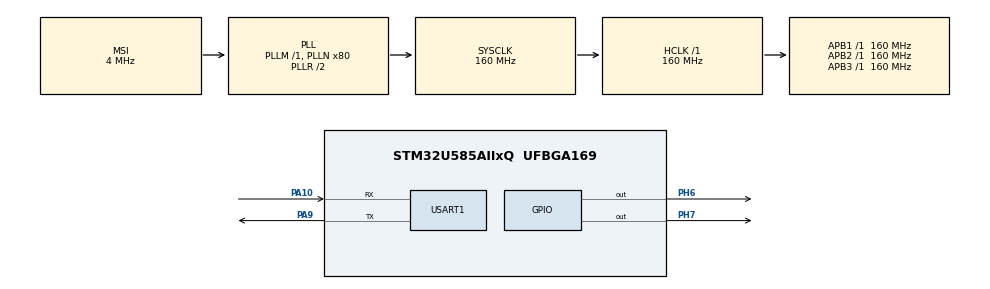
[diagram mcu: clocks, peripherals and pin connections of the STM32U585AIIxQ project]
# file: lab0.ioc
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CORTEX_M33_NS.userName=CORTEX_M33
Mcu.Family=STM32U5
Mcu.Name=STM32U585AIIxQ
Mcu.Package=UFBGA169
NVIC.PriorityGroup=NVIC_PRIORITYGROUP_4
PA10.Mode=Asynchronous
PA10.Signal=USART1_RX
PA9.Mode=Asynchronous
PA9.Signal=USART1_TX
PH6.Signal=GPIO_Output
PH7.Signal=GPIO_Output
PWR.PowerMode=PWR_SMPS_SUPPLY
ProjectManager.HeapSize=0x200
ProjectManager.StackSize=0x400
ProjectManager.TargetToolchain=STM32CubeIDE
RCC.ADCFreq_Value=16000000
RCC.AHBFreq_Value=160000000
RCC.APB1Freq_Value=160000000
RCC.APB1TimFreq_Value=160000000
RCC.APB2Freq_Value=160000000
RCC.APB2TimFreq_Value=160000000
RCC.APB3Freq_Value=160000000
RCC.CortexFreq_Value=160000000
RCC.DACCLockSelectionVirtual=RCC_DAC1CLKSOURCE_LSI
RCC.DACCLockSelectionVirtualString=RCC_DAC1CLKSOURCE_LSI
RCC.EPOD_VALUE=4000000
RCC.HCLKFreq_Value=160000000
RCC.HSE_VALUE=16000000
RCC.HSI48_VALUE=48000000
RCC.HSI_VALUE=16000000
RCC.LSE_VALUE=32768
RCC.LSIDIV_VALUE=32000
RCC.MSI_VALUE=4000000
RCC.PLLN=80
RCC.SYSCLKFreq_VALUE=160000000
RCC.SYSCLKSource=RCC_SYSCLKSOURCE_PLLCLK
RCC.USBFreq_Value=48000000
RCC.VCOOutputFreq_Value=320000000
USART1.VirtualMode-Asynchronous=VM_ASYNC
VP_ICACHE_VS_ICACHE.Mode=DefaultMode
VP_LPBAMQUEUE_VS_QUEUE.Mode=QUEUEMODE
VP_LPBAM_VS_SIG1.Mode=SmartRun
VP_LPBAM_VS_SIG4.Mode=LPDMA1
VP_PWR_VS_DBSignals.Mode=DisableDeadBatterySignals
VP_PWR_VS_LPOM.Mode=PowerOptimisation
VP_PWR_VS_SECSignals.Mode=Security/Privilege
board=B-U585I-IOT02A

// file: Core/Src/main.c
/* USER CODE BEGIN Header */
/**
  ******************************************************************************
  * @file           : main.c
  * @brief          : Main program body
  ******************************************************************************
  * @attention
  *
  * Copyright (c) 2022 STMicroelectronics.
  * All rights reserved.
  *
  * This software is licensed under terms that can be found in the LICENSE file
  * in the root directory of this software component.
  * If no LICENSE file comes with this software, it is provided AS-IS.
  *
  ******************************************************************************
  */
/* USER CODE END Header */
#include "main.h"

/* USER CODE BEGIN Includes */
#include "lab0.h"
/* USER CODE END Includes */

UART_HandleTypeDef huart1;

void SystemClock_Config(void);
static void SystemPower_Config(void);
static void MX_GPIO_Init(void);
static void MX_USART1_UART_Init(void);
static void MX_ICACHE_Init(void);

int main(void)
{

  /* MCU Configuration--------------------------------------------------------*/

  /* Reset of all peripherals, Initializes the Flash interface and the Systick. */
  HAL_Init();

  /* Configure the system clock */
  SystemClock_Config();

  /* Configure the System Power */
  SystemPower_Config();

  /* Initialize all configured peripherals */
  MX_GPIO_Init();
  MX_USART1_UART_Init();
  MX_ICACHE_Init();
  /* USER CODE BEGIN 2 */
  HAL_GPIO_WritePin(GPIOH, GPIO_PIN_6, GPIO_PIN_SET);
  HAL_GPIO_WritePin(GPIOH, GPIO_PIN_7, GPIO_PIN_SET);
  /* USER CODE END 2 */

  /* Infinite loop */

    /* USER CODE BEGIN 3 */
  //task_2();
  //task_3();
  //task_4();
  task_5();
  /* USER CODE END 3 */
}

void SystemClock_Config(void)
{
  RCC_OscInitTypeDef RCC_OscInitStruct = {0};
  RCC_ClkInitTypeDef RCC_ClkInitStruct = {0};

  /** Configure the main internal regulator output voltage
  */
  if (HAL_PWREx_ControlVoltageScaling(PWR_REGULATOR_VOLTAGE_SCALE1) != HAL_OK)
  {
    Error_Handler();
  }

  /** Initializes the CPU, AHB and APB busses clocks
  */
  RCC_OscInitStruct.OscillatorType = RCC_OSCILLATORTYPE_MSI;
  RCC_OscInitStruct.MSIState = RCC_MSI_ON;
  RCC_OscInitStruct.MSICalibrationValue = RCC_MSICALIBRATION_DEFAULT;
  RCC_OscInitStruct.MSIClockRange = RCC_MSIRANGE_4;
  RCC_OscInitStruct.PLL.PLLState = RCC_PLL_ON;
  RCC_OscInitStruct.PLL.PLLSource = RCC_PLLSOURCE_MSI;
  RCC_OscInitStruct.PLL.PLLMBOOST = RCC_PLLMBOOST_DIV1;
  RCC_OscInitStruct.PLL.PLLM = 1;
  RCC_OscInitStruct.PLL.PLLN = 80;
  RCC_OscInitStruct.PLL.PLLP = 2;
  RCC_OscInitStruct.PLL.PLLQ = 2;
  RCC_OscInitStruct.PLL.PLLR = 2;
  RCC_OscInitStruct.PLL.PLLRGE = RCC_PLLVCIRANGE_0;
  RCC_OscInitStruct.PLL.PLLFRACN = 0;
  if (HAL_RCC_OscConfig(&RCC_OscInitStruct) != HAL_OK)
  {
    Error_Handler();
  }

  /** Initializes the CPU, AHB and APB busses clocks
  */
  RCC_ClkInitStruct.ClockType = RCC_CLOCKTYPE_HCLK|RCC_CLOCKTYPE_SYSCLK
                              |RCC_CLOCKTYPE_PCLK1|RCC_CLOCKTYPE_PCLK2
                              |RCC_CLOCKTYPE_PCLK3;
  RCC_ClkInitStruct.SYSCLKSource = RCC_SYSCLKSOURCE_PLLCLK;
  RCC_ClkInitStruct.AHBCLKDivider = RCC_SYSCLK_DIV1;
  RCC_ClkInitStruct.APB1CLKDivider = RCC_HCLK_DIV1;
  RCC_ClkInitStruct.APB2CLKDivider = RCC_HCLK_DIV1;
  RCC_ClkInitStruct.APB3CLKDivider = RCC_HCLK_DIV1;

  if (HAL_RCC_ClockConfig(&RCC_ClkInitStruct, FLASH_LATENCY_4) != HAL_OK)
  {
    Error_Handler();
  }
}

/**
  * @brief Power Configuration
  * @retval None
  */
static void SystemPower_Config(void)
{

  /*
   * Disable the internal Pull-Up in Dead Battery pins of UCPD peripheral
   */
  HAL_PWREx_DisableUCPDDeadBattery();

  /*
   * Switch to SMPS regulator instead of LDO
   */
  if (HAL_PWREx_ConfigSupply(PWR_SMPS_SUPPLY) != HAL_OK)
  {
    Error_Handler();
  }
}

static void MX_ICACHE_Init(void)
{

  /** Enable instruction cache (default 2-ways set associative cache)
  */
  if (HAL_ICACHE_Enable() != HAL_OK)
  {
    Error_Handler();
  }

}

static void MX_USART1_UART_Init(void)
{

  huart1.Instance = USART1;
  huart1.Init.BaudRate = 115200;
  huart1.Init.WordLength = UART_WORDLENGTH_8B;
  huart1.Init.StopBits = UART_STOPBITS_1;
  huart1.Init.Parity = UART_PARITY_NONE;
  huart1.Init.Mode = UART_MODE_TX_RX;
  huart1.Init.HwFlowCtl = UART_HWCONTROL_NONE;
  huart1.Init.OverSampling = UART_OVERSAMPLING_16;
  huart1.Init.OneBitSampling = UART_ONE_BIT_SAMPLE_DISABLE;
  huart1.Init.ClockPrescaler = UART_PRESCALER_DIV1;
  huart1.AdvancedInit.AdvFeatureInit = UART_ADVFEATURE_NO_INIT;
  if (HAL_UART_Init(&huart1) != HAL_OK)
  {
    Error_Handler();
  }
  if (HAL_UARTEx_SetTxFifoThreshold(&huart1, UART_TXFIFO_THRESHOLD_1_8) != HAL_OK)
  {
    Error_Handler();
  }
  if (HAL_UARTEx_SetRxFifoThreshold(&huart1, UART_RXFIFO_THRESHOLD_1_8) != HAL_OK)
  {
    Error_Handler();
  }
  if (HAL_UARTEx_DisableFifoMode(&huart1) != HAL_OK)
  {
    Error_Handler();
  }

}

static void MX_GPIO_Init(void)
{
  GPIO_InitTypeDef GPIO_InitStruct = {0};

  /* GPIO Ports Clock Enable */
  __HAL_RCC_GPIOH_CLK_ENABLE();
  __HAL_RCC_GPIOA_CLK_ENABLE();

  /*Configure GPIO pin Output Level */
  HAL_GPIO_WritePin(GPIOH, GPIO_PIN_6|GPIO_PIN_7, GPIO_PIN_RESET);

  /*Configure GPIO pins : PH6 PH7 */
  GPIO_InitStruct.Pin = GPIO_PIN_6|GPIO_PIN_7;
  GPIO_InitStruct.Mode = GPIO_MODE_OUTPUT_PP;
  GPIO_InitStruct.Pull = GPIO_NOPULL;
  GPIO_InitStruct.Speed = GPIO_SPEED_FREQ_LOW;
  HAL_GPIO_Init(GPIOH, &GPIO_InitStruct);

}

void Error_Handler(void)
{
  __disable_irq();
  while (1)
  {
  }
}
